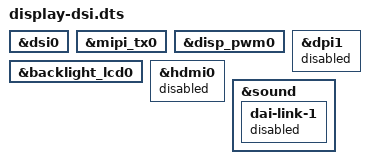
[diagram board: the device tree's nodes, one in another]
/dts-v1/;
/plugin/;

/ {
	fragment@0 {
		target = <&dsi0>;
		__overlay__ {
			status = "okay";
		};
	};

	fragment@1 {
		target = <&mipi_tx0>;
		__overlay__ {
			status = "okay";
		};
	};

	fragment@2 {
		target = <&disp_pwm0>;
		__overlay__ {
			status = "okay";
		};
	};

	fragment@3 {
		target = <&backlight_lcd0>;
		__overlay__ {
			status = "okay";
		};
	};

	fragment@4 {
		target = <&dpi1>;
		__overlay__ {
			status = "disabled";
		};
	};

	fragment@5 {
		target = <&hdmi0>;
		__overlay__ {
			status = "disabled";
		};
	};

	fragment@6 {
		target = <&sound>;
		__overlay__ {
			dai-link-1 {
				status = "disabled";
			};
		};
	};
};
